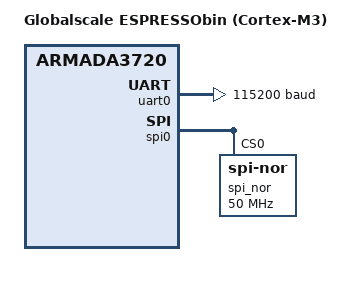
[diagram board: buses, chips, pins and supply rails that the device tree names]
/*
 * Copyright (c) 2026 Jiri Kastner
 *
 * SPDX-License-Identifier: Apache-2.0
 *
 * ESPRESSObin, Cortex-M3 secure processor in place of the WTMI firmware.
 * The console is UART0, shared with the A53 (the BootROM set it up).
 */

/dts-v1/;

#include <freq.h>
#include <marvell/armada3720_cm3.dtsi>

/ {
	model = "Globalscale ESPRESSObin (Cortex-M3)";
	compatible = "globalscale,espressobin";

	chosen {
		zephyr,sram = &sram0;
		zephyr,console = &uart0;
		zephyr,shell-uart = &uart0;
	};
};

&uart0 {
	status = "okay";
	current-speed = <115200>;
	/* the crystal; the BootROM may have left another baud rate */
	clock-frequency = <25000000>;
};

/* W25Q32DW, owned by the CM3 when it serves the flash to the A53
 * (snippet espressobin-cm3-console)
 */
&spi0 {
	pinctrl-0 = <&spi0_default>;
	pinctrl-names = "default";

	spi_nor: flash@0 {
		compatible = "jedec,spi-nor";
		reg = <0>;
		spi-max-frequency = <DT_FREQ_M(50)>;
		size = <DT_SIZE_M(32)>; /* bits */
		jedec-id = [ef 60 16];
	};
};
